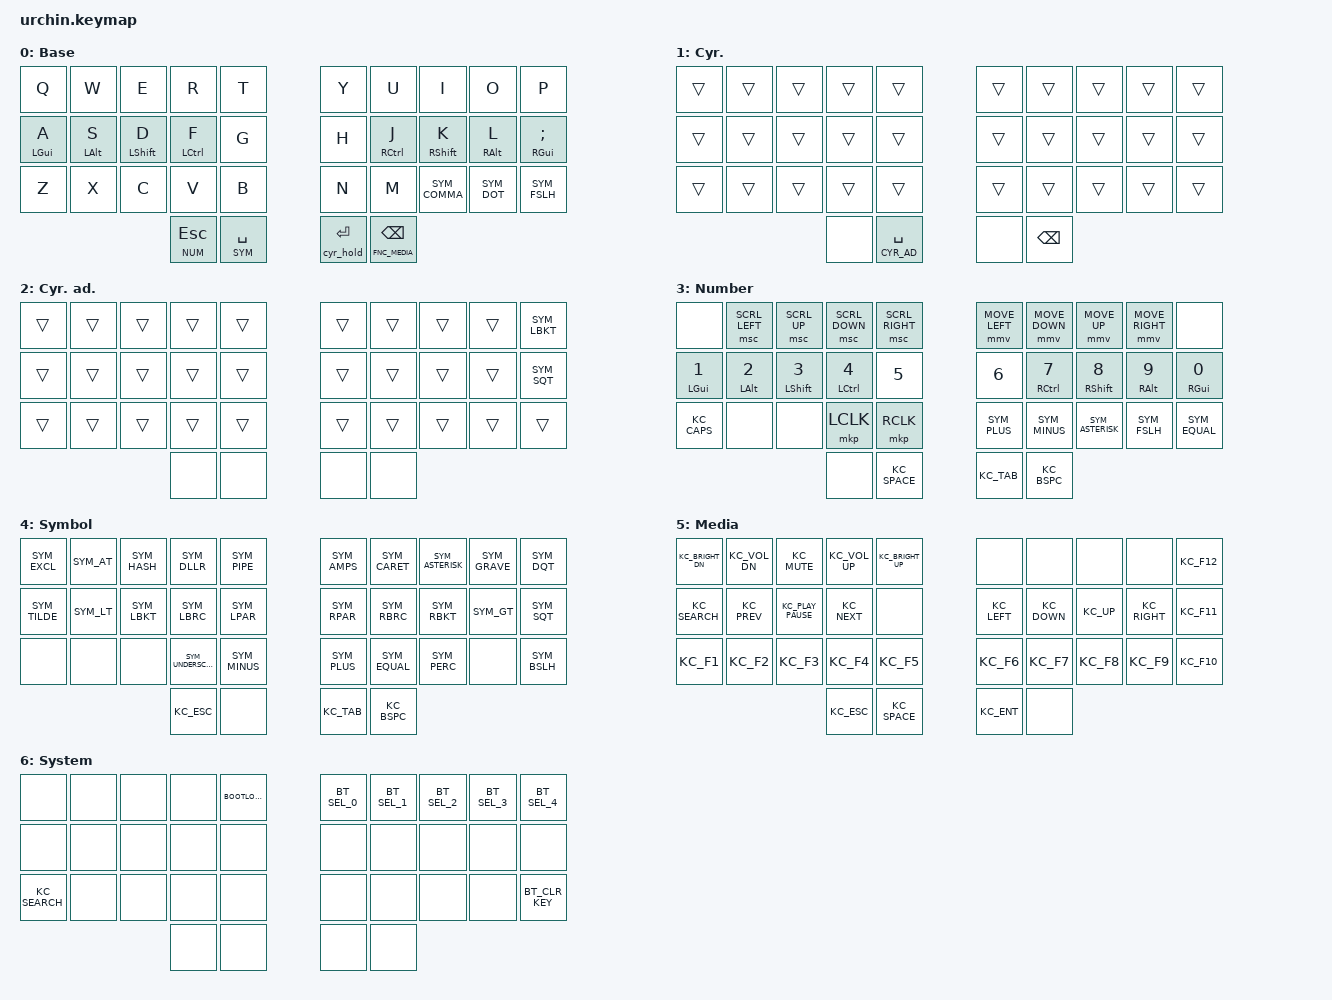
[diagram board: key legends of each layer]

#include <behaviors.dtsi>
#include <dt-bindings/zmk/keys.h>
#include <dt-bindings/zmk/bt.h>
#include <dt-bindings/zmk/outputs.h>
#include <dt-bindings/zmk/hid_usage.h>
#include <dt-bindings/zmk/hid_usage_pages.h>
#include <dt-bindings/zmk/pointing.h>
#include "keymap_symbols.h"

#define BASE 0
#define CYR 1
#define CYR_AD 2
#define NUM 3
#define SYM 4
#define FNC_MEDIA 5
#define SYSTEM_LAYER 6

&sk {
	// don't release mods on other mods presses
	ignore-modifiers;
};


/ {
	behaviors {
		qt: quick_tap {
			compatible = "zmk,behavior-hold-tap";
			label = "QUICK_TAP";
			#binding-cells = <2>;
			flavor = "hold-preferred";
			tapping-term-ms = <200>;
			quick-tap-ms = <200>;
			bindings = <&kp>, <&kp>;
		};

		hm: homerow_mods {
			compatible = "zmk,behavior-hold-tap";
			label = "HOMEROW_MODS";
			#binding-cells = <2>;
			tapping-term-ms = <220>;
			quick-tap-ms = <220>;
			flavor = "tap-preferred";
			bindings = <&kp>, <&kp>;
		};
    cyr_tap: cyr_tap {
      compatible = "zmk,behavior-hold-tap";
      label = "CYRILLIC_TAP";
      #binding-cells = <2>;
      tapping-term-ms = <200>;
      quick-tap-ms = <200>;
      flavor = "tap-preferred";
      bindings = <&cyr_hold>, <&kp>;
    };
	};

	macros {
    cyr_hold: cyr_hold {
      compatible = "zmk,behavior-macro";
      #binding-cells = <0>;
      wait-ms = <0>;
      tap-ms = <0>;
      bindings
        = <&macro_tap &kp F18>
        , <&macro_press &mo CYR>
        , <&macro_pause_for_release>
        , <&macro_release &mo CYR>
        , <&macro_tap &kp F19>;
    };
  };

	combos {
		compatible = "zmk,combos";

		combo_bt_lang {
			timeout-ms = <200>;
			key-positions = <30 31 32 33>;
			bindings = <&mo SYSTEM_LAYER>;
			layers = <BASE>;
		};
	};

	keymap {
		compatible = "zmk,keymap";

		// Base English Alpha Layer
		default_layer {
			label = "Base";
			bindings = <
                &kp Q &kp W &kp E &kp R &kp T           &kp Y &kp U &kp I &kp O &kp P
                &hm LGUI A &hm LALT S &hm LSHFT D &hm LCTRL F &kp G           &kp H &hm RCTRL J &hm RSHFT K &hm RALT L &hm RGUI SCLN
                &kp Z &kp X &kp C &kp V &kp B           &kp N &kp M SYM_COMMA SYM_DOT SYM_FSLH
                                &lt NUM ESC &lt SYM SPACE &cyr_tap 0 ENTER &lt FNC_MEDIA BSPC // Thumb keys with layer-tap
			>;
		};

		cyrillic_layer {
			label = "Cyr.";
			bindings = <
        &trans &trans &trans &trans &trans                   &trans &trans &trans &trans &trans
        &trans &trans &trans &trans &trans                   &trans &trans &trans &trans &trans
        &trans &trans &trans &trans &trans                   &trans &trans &trans &trans &trans
        &none &lt CYR_AD SPACE &none &kp BSPC
			>;
		};

    cyrillic_additional_layer {
      label = "Cyr. ad.";
      bindings = <

        &trans &trans &trans &trans &trans                   &trans &trans &trans &trans SYM_LBKT
        &trans &trans &trans &trans &trans                   &trans &trans &trans &trans SYM_SQT
        &trans &trans &trans &trans &trans                   &trans &trans &trans &trans &trans
        &none &none &none &none
      >;
    };

		// Numbers Layer
		num_layer {
			label = "Number";
			bindings = <
                &none &msc SCRL_LEFT &msc SCRL_UP &msc SCRL_DOWN &msc SCRL_RIGHT           &mmv MOVE_LEFT &mmv MOVE_DOWN &mmv MOVE_UP &mmv MOVE_RIGHT &none
                &hm LGUI N1 &hm LALT N2 &hm LSHFT N3 &hm LCTRL N4 &kp N5      &kp N6 &hm RCTRL N7 &hm RSHFT N8 &hm RALT N9 &hm RGUI N0
                KC_CAPS &none &none &mkp LCLK &mkp RCLK           SYM_PLUS SYM_MINUS SYM_ASTERISK SYM_FSLH SYM_EQUAL
                                &none KC_SPACE KC_TAB KC_BSPC
			>;
		};

		// Symbols Layer
		symb_layer {
			label = "Symbol";
			bindings = <
                SYM_EXCL SYM_AT SYM_HASH SYM_DLLR SYM_PIPE      SYM_AMPS SYM_CARET SYM_ASTERISK SYM_GRAVE SYM_DQT
                SYM_TILDE SYM_LT SYM_LBKT SYM_LBRC SYM_LPAR     SYM_RPAR SYM_RBRC SYM_RBKT SYM_GT  SYM_SQT
                &none &none &none SYM_UNDERSCORE SYM_MINUS      SYM_PLUS SYM_EQUAL SYM_PERC &none SYM_BSLH
                                KC_ESC &none KC_TAB KC_BSPC
			>;
		};

		// Function and Media Keys Layer
		media_layer {
			label = "Media";
			bindings = <
                KC_BRIGHT_DN KC_VOL_DN KC_MUTE KC_VOL_UP KC_BRIGHT_UP   &none &none &none &none KC_F12
                KC_SEARCH KC_PREV KC_PLAY_PAUSE KC_NEXT &none           KC_LEFT KC_DOWN KC_UP KC_RIGHT KC_F11
                KC_F1 KC_F2 KC_F3 KC_F4 KC_F5                           KC_F6 KC_F7 KC_F8 KC_F9 KC_F10
                                KC_ESC KC_SPACE KC_ENT &none
			>;
		};

    system_layer {
      label = "System";
      bindings = <
        &none &none &none &none BOOTLOADER                   BT_SEL_0 BT_SEL_1 BT_SEL_2 BT_SEL_3 BT_SEL_4
        &none &none &none &none &none                   &none &none &none &none &none
        KC_SEARCH &none &none &none &none           &none &none &none &none BT_CLR_KEY
        &none &none &none &none
      >;
    };

  };
};
